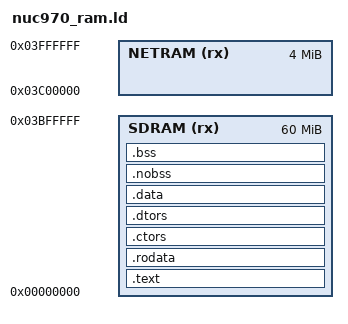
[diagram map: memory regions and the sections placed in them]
OUTPUT_FORMAT("elf32-littlearm", "elf32-littlearm", "elf32-littlearm")
OUTPUT_ARCH(arm)
ENTRY(start)

/* Program Entry, set to mark it as "used" and avoid gc */
MEMORY
{
    SDRAM  (rx) : ORIGIN = 0x00000000, LENGTH = 0x03C00000   /* base code section 60M */
    NETRAM (rx) : ORIGIN = 0x03C00000, LENGTH = 0x00400000   /* base code section  4M */
}
SECTIONS
{
    . = ALIGN(4);
    .text :
    {
        *(.init)
        *(.text)
        *(.gnu.linkonce.t*)

        /* section information for finsh shell */
        . = ALIGN(4);
        __fsymtab_start = .;
        KEEP(*(FSymTab))
        __fsymtab_end = .;
        . = ALIGN(4);
        __vsymtab_start = .;
        KEEP(*(VSymTab))
        __vsymtab_end = .;
        . = ALIGN(4);	

        /* section information for modules */
        . = ALIGN(4);
        __rtmsymtab_start = .;
        KEEP(*(RTMSymTab))
        __rtmsymtab_end = .;

        /* section information for initialization */
        . = ALIGN(4);
        __rt_init_start = .;
        KEEP(*(SORT(.rti_fn*)))
        __rt_init_end = .;
    } > SDRAM=0

    . = ALIGN(4);
    .rodata : { *(.rodata) *(.rodata.*) *(.gnu.linkonce.r*) *(.eh_frame) }> SDRAM

    . = ALIGN(4);
    .ctors :
    {
        PROVIDE(__ctors_start__ = .);
        KEEP(*(SORT(.ctors.*)))
        KEEP(*(.ctors))
        PROVIDE(__ctors_end__ = .);
    }> SDRAM

    .dtors :
    {
        PROVIDE(__dtors_start__ = .);
        KEEP(*(SORT(.dtors.*)))
        KEEP(*(.dtors))
        PROVIDE(__dtors_end__ = .);
    }> SDRAM

    . = ALIGN(4);
    .data :
    {
        *(.data)
        *(.data.*)
        *(.gnu.linkonce.d*)
    }> SDRAM
    
    . = ALIGN(4);
    .nobss : { *(.nobss) }> SDRAM

    . = ALIGN(4);
    __bss_start__ = .;
    .bss : 
    { 
    	*(.bss) 
    	*(.bss.*)
    }> SDRAM
    __bss_end__ = .;

    /* stabs debugging sections. */
    .stab          0 : { *(.stab) }
    .stabstr       0 : { *(.stabstr) }
    .stab.excl     0 : { *(.stab.excl) }
    .stab.exclstr  0 : { *(.stab.exclstr) }
    .stab.index    0 : { *(.stab.index) }
    .stab.indexstr 0 : { *(.stab.indexstr) }
    .comment       0 : { *(.comment) }
    /* DWARF debug sections.
     * Symbols in the DWARF debugging sections are relative to the beginning
     * of the section so we begin them at 0.  */
    /* DWARF 1 */
    .debug          0 : { *(.debug) }
    .line           0 : { *(.line) }
    /* GNU DWARF 1 extensions */
    .debug_srcinfo  0 : { *(.debug_srcinfo) }
    .debug_sfnames  0 : { *(.debug_sfnames) }
    /* DWARF 1.1 and DWARF 2 */
    .debug_aranges  0 : { *(.debug_aranges) }
    .debug_pubnames 0 : { *(.debug_pubnames) }
    /* DWARF 2 */
    .debug_info     0 : { *(.debug_info .gnu.linkonce.wi.*) }
    .debug_abbrev   0 : { *(.debug_abbrev) }
    .debug_line     0 : { *(.debug_line) }
    .debug_frame    0 : { *(.debug_frame) }
    .debug_str      0 : { *(.debug_str) }
    .debug_loc      0 : { *(.debug_loc) }
    .debug_macinfo  0 : { *(.debug_macinfo) }
    /* SGI/MIPS DWARF 2 extensions */
    .debug_weaknames 0 : { *(.debug_weaknames) }
    .debug_funcnames 0 : { *(.debug_funcnames) }
    .debug_typenames 0 : { *(.debug_typenames) }
    .debug_varnames  0 : { *(.debug_varnames) }
    
    _end = .;
}
